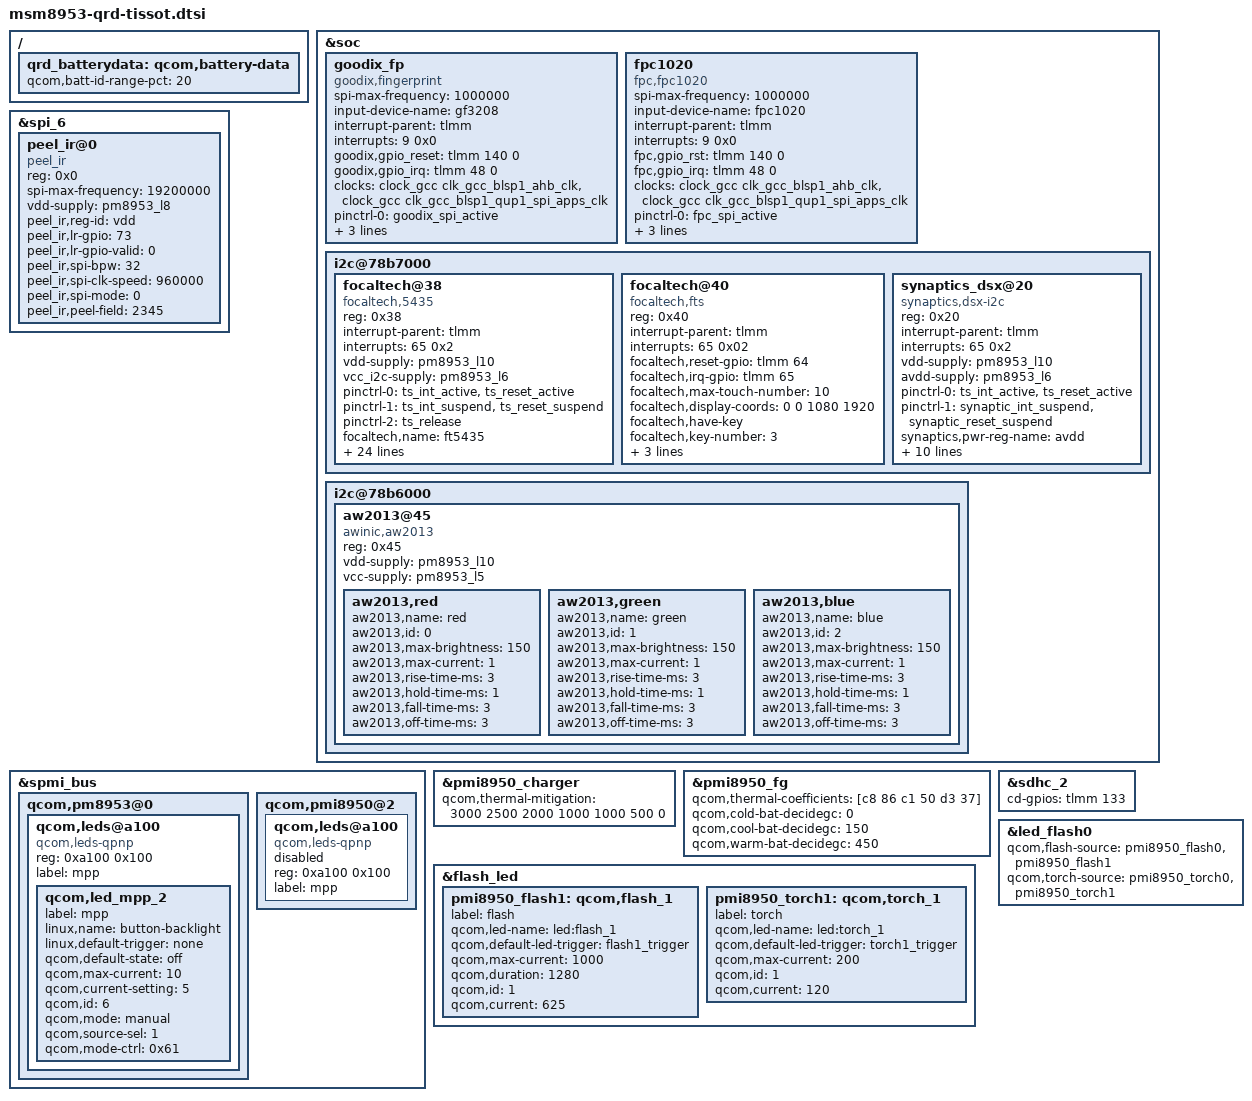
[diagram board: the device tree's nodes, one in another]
/*
 * Copyright (c) 2015-2016, The Linux Foundation. All rights reserved.
 *
 * This program is free software; you can redistribute it and/or modify
 * it under the terms of the GNU General Public License version 2 and
 * only version 2 as published by the Free Software Foundation.
 *
 * This program is distributed in the hope that it will be useful,
 * but WITHOUT ANY WARRANTY; without even the implied warranty of
 * MERCHANTABILITY or FITNESS FOR A PARTICULAR PURPOSE.  See the
 * GNU General Public License for more details.
 */


&soc {
	goodix_fp {
		compatible = "goodix,fingerprint";
		spi-max-frequency = <1000000>;
		input-device-name = "gf3208";
		interrupt-parent = <&tlmm>;
		interrupts = <9 0x0>;

		goodix,gpio_reset    = <&tlmm 140 0>;
		goodix,gpio_irq      = <&tlmm 48 0>;

		clock-names = "iface_clk", "core_clk";
		clocks = <&clock_gcc clk_gcc_blsp1_ahb_clk>,
		<&clock_gcc clk_gcc_blsp1_qup1_spi_apps_clk>;

		pinctrl-names = "goodixfp_spi_active",
			"goodixfp_reset_reset",
			"goodixfp_reset_active",
			"goodixfp_irq_active";

		pinctrl-0 = <&goodix_spi_active>;
		pinctrl-1 = <&goodix_reset_reset>;
		pinctrl-2 = <&goodix_reset_active>;
		pinctrl-3 = <&goodix_irq_active>;
	};
	fpc1020 {
		compatible = "fpc,fpc1020";
		spi-max-frequency = <1000000>;
		input-device-name = "fpc1020";
		interrupt-parent = <&tlmm>;
		interrupts = <9 0x0>;

		fpc,gpio_rst    = <&tlmm 140 0>;
		fpc,gpio_irq      = <&tlmm 48 0>;

		clock-names = "iface_clk", "core_clk";
		clocks = <&clock_gcc clk_gcc_blsp1_ahb_clk>,
		<&clock_gcc clk_gcc_blsp1_qup1_spi_apps_clk>;

		pinctrl-names = "fpc1020_spi_active",
			"fpc1020_reset_reset",
			"fpc1020_reset_active",
			"fpc1020_irq_active";

		pinctrl-0 = <&fpc_spi_active>;
		pinctrl-1 = <&fpc_reset_reset>;
		pinctrl-2 = <&fpc_reset_active>;
		pinctrl-3 = <&fpc_irq_active>;
	};

	i2c@78b7000 { /* BLSP1 QUP3 */
		/delete-node/ synaptics@4b;
		focaltech@38 {
			compatible = "focaltech,5435";
			reg = <0x38>;
			interrupt-parent = <&tlmm>;
			interrupts = <65 0x2>;
			vdd-supply = <&pm8953_l10>;
			vcc_i2c-supply = <&pm8953_l6>;
			/* pins used by touchscreen */
			pinctrl-names = "pmx_ts_active","pmx_ts_suspend",
						"pmx_ts_release";
			pinctrl-0 = <&ts_int_active &ts_reset_active>;
			pinctrl-1 = <&ts_int_suspend &ts_reset_suspend>;
			pinctrl-2 = <&ts_release>;
			focaltech,name = "ft5435";
			focaltech,family-id = <0x54>;
			focaltech,reset-gpio = <&tlmm 64 0x0>;
			focaltech,irq-gpio = <&tlmm 65 0x2008>;
			focaltech,display-coords = <0 0 1080 1920>;
			focaltech,panel-coords = <0 0 1080 1920>;
			focaltech,no-force-update;
			focaltech,i2c-pull-up;
			focaltech,group-id = <1>;
			focaltech,hard-reset-delay-ms = <200>;
			focaltech,soft-reset-delay-ms = <200>;
			focaltech,num-max-touches = <10>;
			focaltech,fw-delay-aa-ms = <2>;
			focaltech,fw-delay-55-ms = <2>;
			focaltech,fw-upgrade-id1 = <0x54>;
			focaltech,fw-upgrade-id2 = <0x2c>;
			focaltech,fw-delay-readid-ms = <10>;
			focaltech,fw-delay-era-flsh-ms = <2000>;
			focaltech,fw-auto-cal;
			focaltech,fw-vkey-support;
			focaltech,resume-in-workqueue;
			focaltech,num-virtual-key = <3>;
			focal,virtual_key_1 = <172 500 2040>;/*home*/
			focal,virtual_key_2 = <139 200 2040>;/*menu*/
			focal,virtual_key_3 = <158 800 2040>;/*back*/
		};
		focaltech@40{
			compatible = "focaltech,fts";
			reg = <0x40>;
			interrupt-parent = <&tlmm>;
			interrupts = <65 0x02>;
			focaltech,reset-gpio = <&tlmm 64 0x0>;
			focaltech,irq-gpio = <&tlmm 65 0x0>;
			focaltech,max-touch-number = <10>;
			focaltech,display-coords =  <0 0 1080 1920>;

			focaltech,have-key;
			focaltech,key-number = <3>;
			focaltech,keys = <139 172 158>;
			focaltech,key-y-coord = <2034>;
			focaltech,key-x-coords = <900 540 180>;
		};
		synaptics_dsx@20 {
			compatible = "synaptics,dsx-i2c";
			reg = <0x20>;
			interrupt-parent = <&tlmm>;
			interrupts = <65 0x2>;
			vdd-supply = <&pm8953_l10>;
			avdd-supply = <&pm8953_l6>;
			pinctrl-names = "pmx_ts_active", "pmx_ts_suspend";
			pinctrl-0 = <&ts_int_active &ts_reset_active>;
			pinctrl-1 = <&synaptic_int_suspend &synaptic_reset_suspend>;
			synaptics,pwr-reg-name = "avdd";
			synaptics,bus-reg-name = "vdd";
			synaptics,ub-i2c-addr = <0x2c>;
			synaptics,irq-gpio = <&tlmm 65 0x2008>; /* IRQF_ONESHOT | IRQF_TRIGGER_LOW */
			synaptics,rst-gpio = <&tlmm 64 0x0>;
			synaptics,irq-on-state = <0>;
			synaptics,power-delay-ms = <200>;
			synaptics,reset-delay-ms = <200>;
			synaptics,reset-on-state = <0>;
			synaptics,reset-active-ms = <20>;
			synaptics,cap-button-codes = <139 172 158>;
		};
	};

	i2c@78b6000 { /* BLSP1 QUP3 */
		aw2013@45 {
			compatible = "awinic,aw2013";
			reg = <0x45>;
			vdd-supply = <&pm8953_l10>;
			vcc-supply = <&pm8953_l5>;

			aw2013,red {
				aw2013,name = "red";
				aw2013,id = <0>;
				aw2013,max-brightness = <150>;
				aw2013,max-current = <1>;
				aw2013,rise-time-ms = <3>;
				aw2013,hold-time-ms = <1>;
				aw2013,fall-time-ms = <3>;
				aw2013,off-time-ms = <3>;
			};
			aw2013,green {
				aw2013,name = "green";
				aw2013,id = <1>;
				aw2013,max-brightness = <150>;
				aw2013,max-current = <1>;
				aw2013,rise-time-ms = <3>;
				aw2013,hold-time-ms = <1>;
				aw2013,fall-time-ms = <3>;
				aw2013,off-time-ms = <3>;
			};
			aw2013,blue {
				aw2013,name = "blue";
				aw2013,id = <2>;
				aw2013,max-brightness = <150>;
				aw2013,max-current = <1>;
				aw2013,rise-time-ms = <3>;
				aw2013,hold-time-ms = <1>;
				aw2013,fall-time-ms = <3>;
				aw2013,off-time-ms = <3>;
			};
		};
	};
};

&spi_6 {
	status = "ok";
	peel_ir@0 {
		compatible = "peel_ir";
		reg = <0x0>;
		spi-max-frequency = <19200000>;
		vdd-supply = <&pm8953_l8>;
		peel_ir,reg-id = "vdd";
		peel_ir,lr-gpio = <73>;
		peel_ir,lr-gpio-valid = <0>;
		peel_ir,spi-bpw = <32>;
		peel_ir,spi-clk-speed = <960000>;
		peel_ir,spi-mode = <0>;
		peel_ir,peel-field = <2345>;
		status = "ok";
	};
};

&spmi_bus {
	qcom,pm8953@0 {
		qcom,leds@a100 {
			status = "okay";
			compatible = "qcom,leds-qpnp";
			reg = <0xa100 0x100>;
			label = "mpp";
			qcom,led_mpp_2 {
				label = "mpp";
				linux,name = "button-backlight";
				linux,default-trigger = "none";
				qcom,default-state = "off";
				qcom,max-current = <10>;
				qcom,current-setting = <5>;
				qcom,id = <6>;
				qcom,mode = "manual";
				qcom,source-sel = <1>;
				qcom,mode-ctrl = <0x61>;
			};
		};
	};

	qcom,pmi8950@2 {
		qcom,leds@a100 {
			compatible = "qcom,leds-qpnp";
			reg = <0xa100 0x100>;
			label = "mpp";
			status = "disable";
			/delete-node/ qcom,led_mpp_2;
		};
	};
};

/ {
	qrd_batterydata: qcom,battery-data {
		qcom,batt-id-range-pct = <20>;
		/delete-node/ qcom,qrd_msm8937_sku1_2920mah;
		#include "batterydata-qrd-coslight-3000mAh.dtsi"
		#include "batterydata-qrd-scud-3000mAh.dtsi"
		#include "batterydata-qrd-sunwoda-liwei-3000mAh.dtsi"
	};
};


&pmi8950_charger {
	/delete-property/ qcom,chg-led-sw-controls;
	/delete-property/ qcom,chg-led-support;
	/delete-property/ qcom,external-typec;
	/delete-property/ qcom,typec-psy-name;
	qcom,thermal-mitigation = <3000 2500 2000 1000 1000 500 0>;
};

&pmi8950_fg {
	qcom,thermal-coefficients = [c8 86 c1 50 d3 37];
	qcom,cold-bat-decidegc = <0>;
	qcom,cool-bat-decidegc = <150>;
	qcom,warm-bat-decidegc = <450>;
};

&sdhc_2 {
	cd-gpios = <&tlmm 133 0x0>;
};

&flash_led {
	pmi8950_flash1: qcom,flash_1 {
		label = "flash";
		qcom,led-name = "led:flash_1";
		qcom,default-led-trigger =
			"flash1_trigger";
		qcom,max-current = <1000>;
		qcom,duration = <1280>;
		qcom,id = <1>;
		qcom,current = <625>;
	};
	pmi8950_torch1: qcom,torch_1 {
		label = "torch";
		qcom,led-name = "led:torch_1";
		qcom,default-led-trigger =
		"torch1_trigger";
		qcom,max-current = <200>;
		qcom,id = <1>;
		qcom,current = <120>;
	};
};

&led_flash0{
	qcom,flash-source = <&pmi8950_flash0 &pmi8950_flash1>;
	qcom,torch-source = <&pmi8950_torch0 &pmi8950_torch1>;
};

